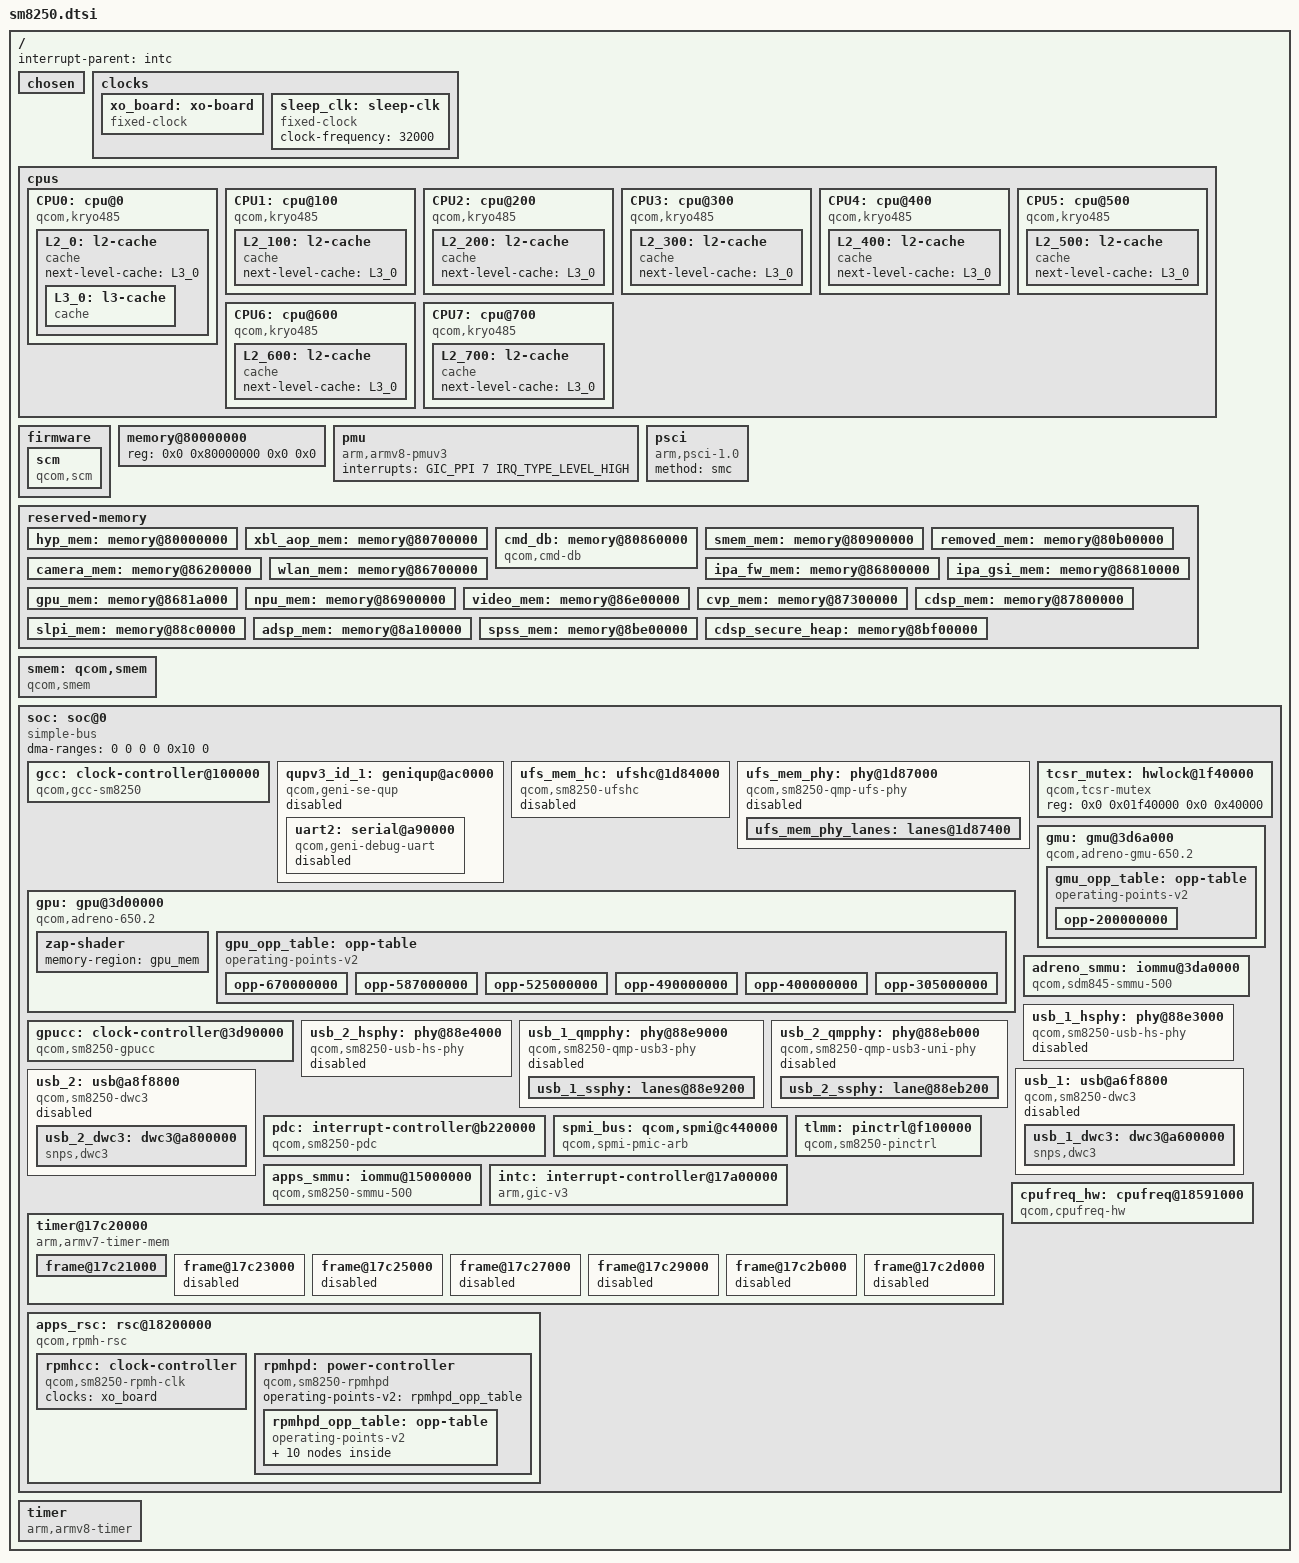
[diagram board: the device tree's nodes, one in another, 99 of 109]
// SPDX-License-Identifier: BSD-3-Clause
/*
 * Copyright (c) 2020, The Linux Foundation. All rights reserved.
 */

#include <dt-bindings/interrupt-controller/arm-gic.h>
#include <dt-bindings/clock/qcom,gcc-sm8250.h>
#include <dt-bindings/clock/qcom,gpucc-sm8250.h>
#include <dt-bindings/clock/qcom,rpmh.h>
#include <dt-bindings/power/qcom-rpmpd.h>
#include <dt-bindings/soc/qcom,rpmh-rsc.h>

/ {
	interrupt-parent = <&intc>;

	#address-cells = <2>;
	#size-cells = <2>;

	chosen { };

	clocks {
		xo_board: xo-board {
			compatible = "fixed-clock";
			#clock-cells = <0>;
			clock-frequency = <38400000>;
			clock-output-names = "xo_board";
		};

		sleep_clk: sleep-clk {
			compatible = "fixed-clock";
			clock-frequency = <32000>;
			#clock-cells = <0>;
		};
	};

	cpus {
		#address-cells = <2>;
		#size-cells = <0>;

		CPU0: cpu@0 {
			device_type = "cpu";
			compatible = "qcom,kryo485";
			reg = <0x0 0x0>;
			enable-method = "psci";
			next-level-cache = <&L2_0>;
			qcom,freq-domain = <&cpufreq_hw 0>;
			L2_0: l2-cache {
			      compatible = "cache";
			      next-level-cache = <&L3_0>;
				L3_0: l3-cache {
				      compatible = "cache";
				};
			};
		};

		CPU1: cpu@100 {
			device_type = "cpu";
			compatible = "qcom,kryo485";
			reg = <0x0 0x100>;
			enable-method = "psci";
			next-level-cache = <&L2_100>;
			qcom,freq-domain = <&cpufreq_hw 0>;
			L2_100: l2-cache {
			      compatible = "cache";
			      next-level-cache = <&L3_0>;
			};
		};

		CPU2: cpu@200 {
			device_type = "cpu";
			compatible = "qcom,kryo485";
			reg = <0x0 0x200>;
			enable-method = "psci";
			next-level-cache = <&L2_200>;
			qcom,freq-domain = <&cpufreq_hw 0>;
			L2_200: l2-cache {
			      compatible = "cache";
			      next-level-cache = <&L3_0>;
			};
		};

		CPU3: cpu@300 {
			device_type = "cpu";
			compatible = "qcom,kryo485";
			reg = <0x0 0x300>;
			enable-method = "psci";
			next-level-cache = <&L2_300>;
			qcom,freq-domain = <&cpufreq_hw 0>;
			L2_300: l2-cache {
			      compatible = "cache";
			      next-level-cache = <&L3_0>;
			};
		};

		CPU4: cpu@400 {
			device_type = "cpu";
			compatible = "qcom,kryo485";
			reg = <0x0 0x400>;
			enable-method = "psci";
			next-level-cache = <&L2_400>;
			qcom,freq-domain = <&cpufreq_hw 1>;
			L2_400: l2-cache {
			      compatible = "cache";
			      next-level-cache = <&L3_0>;
			};
		};

		CPU5: cpu@500 {
			device_type = "cpu";
			compatible = "qcom,kryo485";
			reg = <0x0 0x500>;
			enable-method = "psci";
			next-level-cache = <&L2_500>;
			qcom,freq-domain = <&cpufreq_hw 1>;
			L2_500: l2-cache {
			      compatible = "cache";
			      next-level-cache = <&L3_0>;
			};

		};

		CPU6: cpu@600 {
			device_type = "cpu";
			compatible = "qcom,kryo485";
			reg = <0x0 0x600>;
			enable-method = "psci";
			next-level-cache = <&L2_600>;
			qcom,freq-domain = <&cpufreq_hw 1>;
			L2_600: l2-cache {
			      compatible = "cache";
			      next-level-cache = <&L3_0>;
			};
		};

		CPU7: cpu@700 {
			device_type = "cpu";
			compatible = "qcom,kryo485";
			reg = <0x0 0x700>;
			enable-method = "psci";
			next-level-cache = <&L2_700>;
			qcom,freq-domain = <&cpufreq_hw 2>;
			L2_700: l2-cache {
			      compatible = "cache";
			      next-level-cache = <&L3_0>;
			};
		};
	};

	firmware {
		scm: scm {
			compatible = "qcom,scm";
			#reset-cells = <1>;
		};
	};

	memory@80000000 {
		device_type = "memory";
		/* We expect the bootloader to fill in the size */
		reg = <0x0 0x80000000 0x0 0x0>;
	};

	pmu {
		compatible = "arm,armv8-pmuv3";
		interrupts = <GIC_PPI 7 IRQ_TYPE_LEVEL_HIGH>;
	};

	psci {
		compatible = "arm,psci-1.0";
		method = "smc";
	};

	reserved-memory {
		#address-cells = <2>;
		#size-cells = <2>;
		ranges;

		hyp_mem: memory@80000000 {
			reg = <0x0 0x80000000 0x0 0x600000>;
			no-map;
		};

		xbl_aop_mem: memory@80700000 {
			reg = <0x0 0x80700000 0x0 0x160000>;
			no-map;
		};

		cmd_db: memory@80860000 {
			compatible = "qcom,cmd-db";
			reg = <0x0 0x80860000 0x0 0x20000>;
			no-map;
		};

		smem_mem: memory@80900000 {
			reg = <0x0 0x80900000 0x0 0x200000>;
			no-map;
		};

		removed_mem: memory@80b00000 {
			reg = <0x0 0x80b00000 0x0 0x5300000>;
			no-map;
		};

		camera_mem: memory@86200000 {
			reg = <0x0 0x86200000 0x0 0x500000>;
			no-map;
		};

		wlan_mem: memory@86700000 {
			reg = <0x0 0x86700000 0x0 0x100000>;
			no-map;
		};

		ipa_fw_mem: memory@86800000 {
			reg = <0x0 0x86800000 0x0 0x10000>;
			no-map;
		};

		ipa_gsi_mem: memory@86810000 {
			reg = <0x0 0x86810000 0x0 0xa000>;
			no-map;
		};

		gpu_mem: memory@8681a000 {
			reg = <0x0 0x8681a000 0x0 0x2000>;
			no-map;
		};

		npu_mem: memory@86900000 {
			reg = <0x0 0x86900000 0x0 0x500000>;
			no-map;
		};

		video_mem: memory@86e00000 {
			reg = <0x0 0x86e00000 0x0 0x500000>;
			no-map;
		};

		cvp_mem: memory@87300000 {
			reg = <0x0 0x87300000 0x0 0x500000>;
			no-map;
		};

		cdsp_mem: memory@87800000 {
			reg = <0x0 0x87800000 0x0 0x1400000>;
			no-map;
		};

		slpi_mem: memory@88c00000 {
			reg = <0x0 0x88c00000 0x0 0x1500000>;
			no-map;
		};

		adsp_mem: memory@8a100000 {
			reg = <0x0 0x8a100000 0x0 0x1d00000>;
			no-map;
		};

		spss_mem: memory@8be00000 {
			reg = <0x0 0x8be00000 0x0 0x100000>;
			no-map;
		};

		cdsp_secure_heap: memory@8bf00000 {
			reg = <0x0 0x8bf00000 0x0 0x4600000>;
			no-map;
		};
	};

	smem: qcom,smem {
		compatible = "qcom,smem";
		memory-region = <&smem_mem>;
		hwlocks = <&tcsr_mutex 3>;
	};

	soc: soc@0 {
		#address-cells = <2>;
		#size-cells = <2>;
		ranges = <0 0 0 0 0x10 0>;
		dma-ranges = <0 0 0 0 0x10 0>;
		compatible = "simple-bus";

		gcc: clock-controller@100000 {
			compatible = "qcom,gcc-sm8250";
			reg = <0x0 0x00100000 0x0 0x1f0000>;
			#clock-cells = <1>;
			#reset-cells = <1>;
			#power-domain-cells = <1>;
			clock-names = "bi_tcxo", "sleep_clk";
			clocks = <&rpmhcc RPMH_CXO_CLK>, <&sleep_clk>;
		};

		qupv3_id_1: geniqup@ac0000 {
			compatible = "qcom,geni-se-qup";
			reg = <0x0 0x00ac0000 0x0 0x6000>;
			clock-names = "m-ahb", "s-ahb";
			clocks = <&gcc GCC_QUPV3_WRAP_1_M_AHB_CLK>,
				 <&gcc GCC_QUPV3_WRAP_1_S_AHB_CLK>;
			#address-cells = <2>;
			#size-cells = <2>;
			ranges;
			status = "disabled";

			uart2: serial@a90000 {
				compatible = "qcom,geni-debug-uart";
				reg = <0x0 0x00a90000 0x0 0x4000>;
				clock-names = "se";
				clocks = <&gcc GCC_QUPV3_WRAP1_S4_CLK>;
				interrupts = <GIC_SPI 357 IRQ_TYPE_LEVEL_HIGH>;
				status = "disabled";
			};
		};

		ufs_mem_hc: ufshc@1d84000 {
			compatible = "qcom,sm8250-ufshc", "qcom,ufshc",
				     "jedec,ufs-2.0";
			reg = <0 0x01d84000 0 0x3000>;
			interrupts = <GIC_SPI 265 IRQ_TYPE_LEVEL_HIGH>;
			phys = <&ufs_mem_phy_lanes>;
			phy-names = "ufsphy";
			lanes-per-direction = <2>;
			#reset-cells = <1>;
			resets = <&gcc GCC_UFS_PHY_BCR>;
			reset-names = "rst";

			power-domains = <&gcc UFS_PHY_GDSC>;

			iommus = <&apps_smmu 0x0e0 0>, <&apps_smmu 0x4e0 0>;

			clock-names =
				"core_clk",
				"bus_aggr_clk",
				"iface_clk",
				"core_clk_unipro",
				"ref_clk",
				"tx_lane0_sync_clk",
				"rx_lane0_sync_clk",
				"rx_lane1_sync_clk";
			clocks =
				<&gcc GCC_UFS_PHY_AXI_CLK>,
				<&gcc GCC_AGGRE_UFS_PHY_AXI_CLK>,
				<&gcc GCC_UFS_PHY_AHB_CLK>,
				<&gcc GCC_UFS_PHY_UNIPRO_CORE_CLK>,
				<&rpmhcc RPMH_CXO_CLK>,
				<&gcc GCC_UFS_PHY_TX_SYMBOL_0_CLK>,
				<&gcc GCC_UFS_PHY_RX_SYMBOL_0_CLK>,
				<&gcc GCC_UFS_PHY_RX_SYMBOL_1_CLK>;
			freq-table-hz =
				<37500000 300000000>,
				<0 0>,
				<0 0>,
				<37500000 300000000>,
				<0 0>,
				<0 0>,
				<0 0>,
				<0 0>;

			status = "disabled";
		};

		ufs_mem_phy: phy@1d87000 {
			compatible = "qcom,sm8250-qmp-ufs-phy";
			reg = <0 0x01d87000 0 0x1c0>;
			#address-cells = <2>;
			#size-cells = <2>;
			ranges;
			clock-names = "ref",
				      "ref_aux";
			clocks = <&rpmhcc RPMH_CXO_CLK>,
				 <&gcc GCC_UFS_PHY_PHY_AUX_CLK>;

			resets = <&ufs_mem_hc 0>;
			reset-names = "ufsphy";
			status = "disabled";

			ufs_mem_phy_lanes: lanes@1d87400 {
				reg = <0 0x01d87400 0 0x108>,
				      <0 0x01d87600 0 0x1e0>,
				      <0 0x01d87c00 0 0x1dc>,
				      <0 0x01d87800 0 0x108>,
				      <0 0x01d87a00 0 0x1e0>;
				#phy-cells = <0>;
			};
		};

		tcsr_mutex: hwlock@1f40000 {
			compatible = "qcom,tcsr-mutex";
			reg = <0x0 0x01f40000 0x0 0x40000>;
			#hwlock-cells = <1>;
		};

		gpu: gpu@3d00000 {
			/*
			 * note: the amd,imageon compatible makes it possible
			 * to use the drm/msm driver without the display node,
			 * make sure to remove it when display node is added
			 */
			compatible = "qcom,adreno-650.2",
				     "qcom,adreno",
				     "amd,imageon";
			#stream-id-cells = <16>;

			reg = <0 0x3d00000 0 0x40000>;
			reg-names = "kgsl_3d0_reg_memory";

			interrupts = <GIC_SPI 300 IRQ_TYPE_LEVEL_HIGH>;

			iommus = <&adreno_smmu 0 0x401>;

			operating-points-v2 = <&gpu_opp_table>;

			qcom,gmu = <&gmu>;

			zap-shader {
				memory-region = <&gpu_mem>;
			};

			/* note: downstream checks gpu binning for 670 Mhz */
			gpu_opp_table: opp-table {
				compatible = "operating-points-v2";

				opp-670000000 {
					opp-hz = /bits/ 64 <670000000>;
					opp-level = <RPMH_REGULATOR_LEVEL_NOM_L1>;
				};

				opp-587000000 {
					opp-hz = /bits/ 64 <587000000>;
					opp-level = <RPMH_REGULATOR_LEVEL_NOM>;
				};

				opp-525000000 {
					opp-hz = /bits/ 64 <525000000>;
					opp-level = <RPMH_REGULATOR_LEVEL_SVS_L2>;
				};

				opp-490000000 {
					opp-hz = /bits/ 64 <490000000>;
					opp-level = <RPMH_REGULATOR_LEVEL_SVS_L1>;
				};

				/* opp-441600000 {
					opp-hz = /bits/ 64 <441600000>;
					opp-level = <RPMH_REGULATOR_LEVEL_SVS_L0>;
				}; */

				opp-400000000 {
					opp-hz = /bits/ 64 <400000000>;
					opp-level = <RPMH_REGULATOR_LEVEL_SVS>;
				};

				opp-305000000 {
					opp-hz = /bits/ 64 <305000000>;
					opp-level = <RPMH_REGULATOR_LEVEL_LOW_SVS>;
				};
			};
		};

		gmu: gmu@3d6a000 {
			compatible="qcom,adreno-gmu-650.2", "qcom,adreno-gmu";

			reg = <0 0x3d6a000 0 0x30000>,
			      <0 0x3de0000 0 0x10000>,
			      <0 0xb290000 0 0x10000>,
			      <0 0xb490000 0 0x10000>;
			reg-names = "gmu", "rscc", "gmu_pdc", "gmu_pdc_seq";

			interrupts = <GIC_SPI 304 IRQ_TYPE_LEVEL_HIGH>,
				     <GIC_SPI 305 IRQ_TYPE_LEVEL_HIGH>;
			interrupt-names = "hfi", "gmu";

			clocks = <&gpucc GPU_CC_AHB_CLK>,
				 <&gpucc GPU_CC_CX_GMU_CLK>,
			         <&gpucc GPU_CC_CXO_CLK>,
				 <&gcc GCC_DDRSS_GPU_AXI_CLK>,
				 <&gcc GCC_GPU_MEMNOC_GFX_CLK>;
			clock-names = "ahb", "gmu", "cxo", "axi", "memnoc";

			power-domains = <&gpucc GPU_CX_GDSC>,
					<&gpucc GPU_GX_GDSC>;
			power-domain-names = "cx", "gx";

			iommus = <&adreno_smmu 5 0x400>;

			operating-points-v2 = <&gmu_opp_table>;

			gmu_opp_table: opp-table {
				compatible = "operating-points-v2";

				opp-200000000 {
					opp-hz = /bits/ 64 <200000000>;
					opp-level = <RPMH_REGULATOR_LEVEL_MIN_SVS>;
				};
			};
		};

		gpucc: clock-controller@3d90000 {
			compatible = "qcom,sm8250-gpucc";
			reg = <0 0x3d90000 0 0x9000>;
			#clock-cells = <1>;
			#reset-cells = <1>;
			#power-domain-cells = <1>;
			clocks = <&rpmhcc RPMH_CXO_CLK>;
			clock-names = "xo";
		};

		adreno_smmu: iommu@3da0000 {
			compatible = "qcom,sdm845-smmu-500", "arm,mmu-500";
			reg = <0 0x3da0000 0 0x10000>;
			#iommu-cells = <2>;
			#global-interrupts = <2>;
			interrupts = <GIC_SPI 672 IRQ_TYPE_LEVEL_HIGH>,
				     <GIC_SPI 673 IRQ_TYPE_LEVEL_HIGH>,
				     <GIC_SPI 678 IRQ_TYPE_LEVEL_HIGH>,
				     <GIC_SPI 679 IRQ_TYPE_LEVEL_HIGH>,
				     <GIC_SPI 680 IRQ_TYPE_LEVEL_HIGH>,
				     <GIC_SPI 681 IRQ_TYPE_LEVEL_HIGH>,
				     <GIC_SPI 682 IRQ_TYPE_LEVEL_HIGH>,
				     <GIC_SPI 683 IRQ_TYPE_LEVEL_HIGH>,
				     <GIC_SPI 684 IRQ_TYPE_LEVEL_HIGH>,
				     <GIC_SPI 685 IRQ_TYPE_LEVEL_HIGH>;
			clocks = <&gpucc GPU_CC_AHB_CLK>,
				 <&gcc GCC_GPU_MEMNOC_GFX_CLK>,
				 <&gcc GCC_GPU_SNOC_DVM_GFX_CLK>;
			clock-names = "ahb", "bus", "iface";

			power-domains = <&gpucc GPU_CX_GDSC>;
		};

		usb_1_hsphy: phy@88e3000 {
			compatible = "qcom,sm8250-usb-hs-phy",
				     "qcom,usb-snps-hs-7nm-phy";
			reg = <0 0x088e3000 0 0x400>;
			status = "disabled";
			#phy-cells = <0>;

			clocks = <&rpmhcc RPMH_CXO_CLK>;
			clock-names = "ref";

			resets = <&gcc GCC_QUSB2PHY_PRIM_BCR>;
		};

		usb_2_hsphy: phy@88e4000 {
			compatible = "qcom,sm8250-usb-hs-phy",
				     "qcom,usb-snps-hs-7nm-phy";
			reg = <0 0x088e4000 0 0x400>;
			status = "disabled";
			#phy-cells = <0>;

			clocks = <&rpmhcc RPMH_CXO_CLK>;
			clock-names = "ref";

			resets = <&gcc GCC_QUSB2PHY_SEC_BCR>;
		};

		usb_1_qmpphy: phy@88e9000 {
			compatible = "qcom,sm8250-qmp-usb3-phy";
			reg = <0 0x088e9000 0 0x200>,
			      <0 0x088e8000 0 0x20>;
			reg-names = "reg-base", "dp_com";
			status = "disabled";
			#clock-cells = <1>;
			#address-cells = <2>;
			#size-cells = <2>;
			ranges;

			clocks = <&gcc GCC_USB3_PRIM_PHY_AUX_CLK>,
				 <&rpmhcc RPMH_CXO_CLK>,
				 <&gcc GCC_USB3_PRIM_PHY_COM_AUX_CLK>;
			clock-names = "aux", "ref_clk_src", "com_aux";

			resets = <&gcc GCC_USB3_DP_PHY_PRIM_BCR>,
				 <&gcc GCC_USB3_PHY_PRIM_BCR>;
			reset-names = "phy", "common";

			usb_1_ssphy: lanes@88e9200 {
				reg = <0 0x088e9200 0 0x200>,
				      <0 0x088e9400 0 0x200>,
				      <0 0x088e9c00 0 0x400>,
				      <0 0x088e9600 0 0x200>,
				      <0 0x088e9800 0 0x200>,
				      <0 0x088e9a00 0 0x100>;
				#phy-cells = <0>;
				clocks = <&gcc GCC_USB3_PRIM_PHY_PIPE_CLK>;
				clock-names = "pipe0";
				clock-output-names = "usb3_phy_pipe_clk_src";
			};
		};

		usb_2_qmpphy: phy@88eb000 {
			compatible = "qcom,sm8250-qmp-usb3-uni-phy";
			reg = <0 0x088eb000 0 0x200>;
			status = "disabled";
			#clock-cells = <1>;
			#address-cells = <2>;
			#size-cells = <2>;
			ranges;

			clocks = <&gcc GCC_USB3_SEC_PHY_AUX_CLK>,
				 <&rpmhcc RPMH_CXO_CLK>,
				 <&gcc GCC_USB3_SEC_CLKREF_EN>,
				 <&gcc GCC_USB3_SEC_PHY_COM_AUX_CLK>;
			clock-names = "aux", "ref_clk_src", "ref", "com_aux";

			resets = <&gcc GCC_USB3PHY_PHY_SEC_BCR>,
				 <&gcc GCC_USB3_PHY_SEC_BCR>;
			reset-names = "phy", "common";

			usb_2_ssphy: lane@88eb200 {
				reg = <0 0x088eb200 0 0x200>,
				      <0 0x088eb400 0 0x200>,
				      <0 0x088eb800 0 0x800>;
				#phy-cells = <0>;
				clocks = <&gcc GCC_USB3_SEC_PHY_PIPE_CLK>;
				clock-names = "pipe0";
				clock-output-names = "usb3_uni_phy_pipe_clk_src";
			};
		};

		usb_1: usb@a6f8800 {
			compatible = "qcom,sm8250-dwc3", "qcom,dwc3";
			reg = <0 0x0a6f8800 0 0x400>;
			status = "disabled";
			#address-cells = <2>;
			#size-cells = <2>;
			ranges;
			dma-ranges;

			clocks = <&gcc GCC_CFG_NOC_USB3_PRIM_AXI_CLK>,
				 <&gcc GCC_USB30_PRIM_MASTER_CLK>,
				 <&gcc GCC_AGGRE_USB3_PRIM_AXI_CLK>,
				 <&gcc GCC_USB30_PRIM_MOCK_UTMI_CLK>,
				 <&gcc GCC_USB30_PRIM_SLEEP_CLK>,
				 <&gcc GCC_USB3_SEC_CLKREF_EN>;
			clock-names = "cfg_noc", "core", "iface", "mock_utmi",
				      "sleep", "xo";

			assigned-clocks = <&gcc GCC_USB30_PRIM_MOCK_UTMI_CLK>,
					  <&gcc GCC_USB30_PRIM_MASTER_CLK>;
			assigned-clock-rates = <19200000>, <200000000>;

			interrupts-extended = <&intc GIC_SPI 131 IRQ_TYPE_LEVEL_HIGH>,
					      <&pdc 14 IRQ_TYPE_EDGE_BOTH>,
					      <&pdc 15 IRQ_TYPE_EDGE_BOTH>,
					      <&pdc 17 IRQ_TYPE_LEVEL_HIGH>;
			interrupt-names = "hs_phy_irq", "dp_hs_phy_irq",
					  "dm_hs_phy_irq", "ss_phy_irq";

			power-domains = <&gcc USB30_PRIM_GDSC>;

			resets = <&gcc GCC_USB30_PRIM_BCR>;

			usb_1_dwc3: dwc3@a600000 {
				compatible = "snps,dwc3";
				reg = <0 0x0a600000 0 0xcd00>;
				interrupts = <GIC_SPI 133 IRQ_TYPE_LEVEL_HIGH>;
				iommus = <&apps_smmu 0x0 0x0>;
				snps,dis_u2_susphy_quirk;
				snps,dis_enblslpm_quirk;
				phys = <&usb_1_hsphy>, <&usb_1_ssphy>;
				phy-names = "usb2-phy", "usb3-phy";
			};
		};

		usb_2: usb@a8f8800 {
			compatible = "qcom,sm8250-dwc3", "qcom,dwc3";
			reg = <0 0x0a8f8800 0 0x400>;
			status = "disabled";
			#address-cells = <2>;
			#size-cells = <2>;
			ranges;
			dma-ranges;

			clocks = <&gcc GCC_CFG_NOC_USB3_SEC_AXI_CLK>,
				 <&gcc GCC_USB30_SEC_MASTER_CLK>,
				 <&gcc GCC_AGGRE_USB3_SEC_AXI_CLK>,
				 <&gcc GCC_USB30_SEC_MOCK_UTMI_CLK>,
				 <&gcc GCC_USB30_SEC_SLEEP_CLK>,
				 <&gcc GCC_USB3_SEC_CLKREF_EN>;
			clock-names = "cfg_noc", "core", "iface", "mock_utmi",
				      "sleep", "xo";

			assigned-clocks = <&gcc GCC_USB30_SEC_MOCK_UTMI_CLK>,
					  <&gcc GCC_USB30_SEC_MASTER_CLK>;
			assigned-clock-rates = <19200000>, <200000000>;

			interrupts-extended = <&intc GIC_SPI 136 IRQ_TYPE_LEVEL_HIGH>,
					      <&pdc 12 IRQ_TYPE_EDGE_BOTH>,
					      <&pdc 13 IRQ_TYPE_EDGE_BOTH>,
					      <&pdc 16 IRQ_TYPE_LEVEL_HIGH>;
			interrupt-names = "hs_phy_irq", "dp_hs_phy_irq",
					  "dm_hs_phy_irq", "ss_phy_irq";

			power-domains = <&gcc USB30_SEC_GDSC>;

			resets = <&gcc GCC_USB30_SEC_BCR>;

			usb_2_dwc3: dwc3@a800000 {
				compatible = "snps,dwc3";
				reg = <0 0x0a800000 0 0xcd00>;
				interrupts = <GIC_SPI 138 IRQ_TYPE_LEVEL_HIGH>;
				iommus = <&apps_smmu 0x20 0>;
				snps,dis_u2_susphy_quirk;
				snps,dis_enblslpm_quirk;
				phys = <&usb_2_hsphy>, <&usb_2_ssphy>;
				phy-names = "usb2-phy", "usb3-phy";
			};
		};

		pdc: interrupt-controller@b220000 {
			compatible = "qcom,sm8250-pdc", "qcom,pdc";
			reg = <0 0x0b220000 0 0x30000>, <0 0x17c000f0 0 0x60>;
			qcom,pdc-ranges = <0 480 94>, <94 609 31>,
					  <125 63 1>, <126 716 12>;
			#interrupt-cells = <2>;
			interrupt-parent = <&intc>;
			interrupt-controller;
		};

		spmi_bus: qcom,spmi@c440000 {
			compatible = "qcom,spmi-pmic-arb";
			reg = <0x0 0x0c440000 0x0 0x0001100>,
			      <0x0 0x0c600000 0x0 0x2000000>,
			      <0x0 0x0e600000 0x0 0x0100000>,
			      <0x0 0x0e700000 0x0 0x00a0000>,
			      <0x0 0x0c40a000 0x0 0x0026000>;
			reg-names = "core", "chnls", "obsrvr", "intr", "cnfg";
			interrupt-names = "periph_irq";
			interrupts-extended = <&pdc 1 IRQ_TYPE_LEVEL_HIGH>;
			qcom,ee = <0>;
			qcom,channel = <0>;
			#address-cells = <2>;
			#size-cells = <0>;
			interrupt-controller;
			#interrupt-cells = <4>;
		};

		tlmm: pinctrl@f100000 {
			compatible = "qcom,sm8250-pinctrl";
			reg = <0 0x0f100000 0 0x300000>,
			      <0 0x0f500000 0 0x300000>,
			      <0 0x0f900000 0 0x300000>;
			reg-names = "west", "south", "north";
			interrupts = <GIC_SPI 208 IRQ_TYPE_LEVEL_HIGH>;
			gpio-controller;
			#gpio-cells = <2>;
			interrupt-controller;
			#interrupt-cells = <2>;
			gpio-ranges = <&tlmm 0 0 180>;
			wakeup-parent = <&pdc>;
		};

		apps_smmu: iommu@15000000 {
			compatible = "qcom,sm8250-smmu-500", "arm,mmu-500";
			reg = <0 0x15000000 0 0x100000>;
			#iommu-cells = <2>;
			#global-interrupts = <2>;
			interrupts =    <GIC_SPI 64 IRQ_TYPE_LEVEL_HIGH>,
					<GIC_SPI 65 IRQ_TYPE_LEVEL_HIGH>,
					<GIC_SPI 97 IRQ_TYPE_LEVEL_HIGH>,
					<GIC_SPI 98 IRQ_TYPE_LEVEL_HIGH>,
					<GIC_SPI 99 IRQ_TYPE_LEVEL_HIGH>,
					<GIC_SPI 100 IRQ_TYPE_LEVEL_HIGH>,
					<GIC_SPI 101 IRQ_TYPE_LEVEL_HIGH>,
					<GIC_SPI 102 IRQ_TYPE_LEVEL_HIGH>,
					<GIC_SPI 103 IRQ_TYPE_LEVEL_HIGH>,
					<GIC_SPI 104 IRQ_TYPE_LEVEL_HIGH>,
					<GIC_SPI 105 IRQ_TYPE_LEVEL_HIGH>,
					<GIC_SPI 106 IRQ_TYPE_LEVEL_HIGH>,
					<GIC_SPI 107 IRQ_TYPE_LEVEL_HIGH>,
					<GIC_SPI 108 IRQ_TYPE_LEVEL_HIGH>,
					<GIC_SPI 109 IRQ_TYPE_LEVEL_HIGH>,
					<GIC_SPI 110 IRQ_TYPE_LEVEL_HIGH>,
					<GIC_SPI 111 IRQ_TYPE_LEVEL_HIGH>,
					<GIC_SPI 112 IRQ_TYPE_LEVEL_HIGH>,
					<GIC_SPI 113 IRQ_TYPE_LEVEL_HIGH>,
					<GIC_SPI 114 IRQ_TYPE_LEVEL_HIGH>,
					<GIC_SPI 115 IRQ_TYPE_LEVEL_HIGH>,
					<GIC_SPI 116 IRQ_TYPE_LEVEL_HIGH>,
					<GIC_SPI 117 IRQ_TYPE_LEVEL_HIGH>,
					<GIC_SPI 118 IRQ_TYPE_LEVEL_HIGH>,
					<GIC_SPI 181 IRQ_TYPE_LEVEL_HIGH>,
					<GIC_SPI 182 IRQ_TYPE_LEVEL_HIGH>,
					<GIC_SPI 183 IRQ_TYPE_LEVEL_HIGH>,
					<GIC_SPI 184 IRQ_TYPE_LEVEL_HIGH>,
					<GIC_SPI 185 IRQ_TYPE_LEVEL_HIGH>,
					<GIC_SPI 186 IRQ_TYPE_LEVEL_HIGH>,
					<GIC_SPI 187 IRQ_TYPE_LEVEL_HIGH>,
					<GIC_SPI 188 IRQ_TYPE_LEVEL_HIGH>,
					<GIC_SPI 189 IRQ_TYPE_LEVEL_HIGH>,
					<GIC_SPI 190 IRQ_TYPE_LEVEL_HIGH>,
					<GIC_SPI 191 IRQ_TYPE_LEVEL_HIGH>,
					<GIC_SPI 192 IRQ_TYPE_LEVEL_HIGH>,
					<GIC_SPI 315 IRQ_TYPE_LEVEL_HIGH>,
					<GIC_SPI 316 IRQ_TYPE_LEVEL_HIGH>,
					<GIC_SPI 317 IRQ_TYPE_LEVEL_HIGH>,
					<GIC_SPI 318 IRQ_TYPE_LEVEL_HIGH>,
					<GIC_SPI 319 IRQ_TYPE_LEVEL_HIGH>,
					<GIC_SPI 320 IRQ_TYPE_LEVEL_HIGH>,
					<GIC_SPI 321 IRQ_TYPE_LEVEL_HIGH>,
					<GIC_SPI 322 IRQ_TYPE_LEVEL_HIGH>,
					<GIC_SPI 323 IRQ_TYPE_LEVEL_HIGH>,
					<GIC_SPI 324 IRQ_TYPE_LEVEL_HIGH>,
					<GIC_SPI 325 IRQ_TYPE_LEVEL_HIGH>,
					<GIC_SPI 326 IRQ_TYPE_LEVEL_HIGH>,
					<GIC_SPI 327 IRQ_TYPE_LEVEL_HIGH>,
					<GIC_SPI 328 IRQ_TYPE_LEVEL_HIGH>,
					<GIC_SPI 329 IRQ_TYPE_LEVEL_HIGH>,
					<GIC_SPI 330 IRQ_TYPE_LEVEL_HIGH>,
					<GIC_SPI 331 IRQ_TYPE_LEVEL_HIGH>,
					<GIC_SPI 332 IRQ_TYPE_LEVEL_HIGH>,
					<GIC_SPI 333 IRQ_TYPE_LEVEL_HIGH>,
					<GIC_SPI 334 IRQ_TYPE_LEVEL_HIGH>,
					<GIC_SPI 335 IRQ_TYPE_LEVEL_HIGH>,
					<GIC_SPI 336 IRQ_TYPE_LEVEL_HIGH>,
					<GIC_SPI 337 IRQ_TYPE_LEVEL_HIGH>,
					<GIC_SPI 338 IRQ_TYPE_LEVEL_HIGH>,
					<GIC_SPI 339 IRQ_TYPE_LEVEL_HIGH>,
					<GIC_SPI 340 IRQ_TYPE_LEVEL_HIGH>,
					<GIC_SPI 341 IRQ_TYPE_LEVEL_HIGH>,
					<GIC_SPI 342 IRQ_TYPE_LEVEL_HIGH>,
					<GIC_SPI 343 IRQ_TYPE_LEVEL_HIGH>,
					<GIC_SPI 344 IRQ_TYPE_LEVEL_HIGH>,
					<GIC_SPI 345 IRQ_TYPE_LEVEL_HIGH>,
					<GIC_SPI 395 IRQ_TYPE_LEVEL_HIGH>,
					<GIC_SPI 396 IRQ_TYPE_LEVEL_HIGH>,
					<GIC_SPI 397 IRQ_TYPE_LEVEL_HIGH>,
					<GIC_SPI 398 IRQ_TYPE_LEVEL_HIGH>,
					<GIC_SPI 399 IRQ_TYPE_LEVEL_HIGH>,
					<GIC_SPI 400 IRQ_TYPE_LEVEL_HIGH>,
					<GIC_SPI 401 IRQ_TYPE_LEVEL_HIGH>,
					<GIC_SPI 402 IRQ_TYPE_LEVEL_HIGH>,
					<GIC_SPI 403 IRQ_TYPE_LEVEL_HIGH>,
					<GIC_SPI 404 IRQ_TYPE_LEVEL_HIGH>,
					<GIC_SPI 405 IRQ_TYPE_LEVEL_HIGH>,
					<GIC_SPI 406 IRQ_TYPE_LEVEL_HIGH>,
					<GIC_SPI 407 IRQ_TYPE_LEVEL_HIGH>,
					<GIC_SPI 408 IRQ_TYPE_LEVEL_HIGH>,
					<GIC_SPI 409 IRQ_TYPE_LEVEL_HIGH>,
					<GIC_SPI 412 IRQ_TYPE_LEVEL_HIGH>,
					<GIC_SPI 418 IRQ_TYPE_LEVEL_HIGH>,
					<GIC_SPI 419 IRQ_TYPE_LEVEL_HIGH>,
					<GIC_SPI 421 IRQ_TYPE_LEVEL_HIGH>,
					<GIC_SPI 423 IRQ_TYPE_LEVEL_HIGH>,
					<GIC_SPI 424 IRQ_TYPE_LEVEL_HIGH>,
					<GIC_SPI 425 IRQ_TYPE_LEVEL_HIGH>,
					<GIC_SPI 690 IRQ_TYPE_LEVEL_HIGH>,
					<GIC_SPI 691 IRQ_TYPE_LEVEL_HIGH>,
					<GIC_SPI 692 IRQ_TYPE_LEVEL_HIGH>,
					<GIC_SPI 693 IRQ_TYPE_LEVEL_HIGH>,
					<GIC_SPI 694 IRQ_TYPE_LEVEL_HIGH>,
					<GIC_SPI 695 IRQ_TYPE_LEVEL_HIGH>,
					<GIC_SPI 696 IRQ_TYPE_LEVEL_HIGH>,
					<GIC_SPI 697 IRQ_TYPE_LEVEL_HIGH>,
					<GIC_SPI 707 IRQ_TYPE_LEVEL_HIGH>;
		};

		intc: interrupt-controller@17a00000 {
			compatible = "arm,gic-v3";
			#interrupt-cells = <3>;
			interrupt-controller;
			reg = <0x0 0x17a00000 0x0 0x10000>,     /* GICD */
			      <0x0 0x17a60000 0x0 0x100000>;    /* GICR * 8 */
			interrupts = <GIC_PPI 9 IRQ_TYPE_LEVEL_HIGH>;
		};

		timer@17c20000 {
			#address-cells = <2>;
			#size-cells = <2>;
			ranges;
			compatible = "arm,armv7-timer-mem";
			reg = <0x0 0x17c20000 0x0 0x1000>;
			clock-frequency = <19200000>;

			frame@17c21000 {
				frame-number = <0>;
				interrupts = <GIC_SPI 8 IRQ_TYPE_LEVEL_HIGH>,
					     <GIC_SPI 6 IRQ_TYPE_LEVEL_HIGH>;
				reg = <0x0 0x17c21000 0x0 0x1000>,
				      <0x0 0x17c22000 0x0 0x1000>;
			};

			frame@17c23000 {
				frame-number = <1>;
				interrupts = <GIC_SPI 9 IRQ_TYPE_LEVEL_HIGH>;
				reg = <0x0 0x17c23000 0x0 0x1000>;
				status = "disabled";
			};

			frame@17c25000 {
				frame-number = <2>;
				interrupts = <GIC_SPI 10 IRQ_TYPE_LEVEL_HIGH>;
				reg = <0x0 0x17c25000 0x0 0x1000>;
				status = "disabled";
			};

			frame@17c27000 {
				frame-number = <3>;
				interrupts = <GIC_SPI 11 IRQ_TYPE_LEVEL_HIGH>;
				reg = <0x0 0x17c27000 0x0 0x1000>;
				status = "disabled";
			};

			frame@17c29000 {
				frame-number = <4>;
				interrupts = <GIC_SPI 12 IRQ_TYPE_LEVEL_HIGH>;
				reg = <0x0 0x17c29000 0x0 0x1000>;
				status = "disabled";
			};

			frame@17c2b000 {
				frame-number = <5>;
				interrupts = <GIC_SPI 13 IRQ_TYPE_LEVEL_HIGH>;
				reg = <0x0 0x17c2b000 0x0 0x1000>;
				status = "disabled";
			};

			frame@17c2d000 {
				frame-number = <6>;
				interrupts = <GIC_SPI 14 IRQ_TYPE_LEVEL_HIGH>;
				reg = <0x0 0x17c2d000 0x0 0x1000>;
				status = "disabled";
			};
		};

		apps_rsc: rsc@18200000 {
			label = "apps_rsc";
			compatible = "qcom,rpmh-rsc";
			reg = <0x0 0x18200000 0x0 0x10000>,
				<0x0 0x18210000 0x0 0x10000>,
				<0x0 0x18220000 0x0 0x10000>;
			reg-names = "drv-0", "drv-1", "drv-2";
			interrupts = <GIC_SPI 3 IRQ_TYPE_LEVEL_HIGH>,
				     <GIC_SPI 4 IRQ_TYPE_LEVEL_HIGH>,
				     <GIC_SPI 5 IRQ_TYPE_LEVEL_HIGH>;
			qcom,tcs-offset = <0xd00>;
			qcom,drv-id = <2>;
			qcom,tcs-config = <ACTIVE_TCS  2>, <SLEEP_TCS   3>,
					  <WAKE_TCS    3>, <CONTROL_TCS 1>;

			rpmhcc: clock-controller {
				compatible = "qcom,sm8250-rpmh-clk";
				#clock-cells = <1>;
				clock-names = "xo";
				clocks = <&xo_board>;
			};

			rpmhpd: power-controller {
				compatible = "qcom,sm8250-rpmhpd";
				#power-domain-cells = <1>;
				operating-points-v2 = <&rpmhpd_opp_table>;

				rpmhpd_opp_table: opp-table {
					compatible = "operating-points-v2";

					rpmhpd_opp_ret: opp1 {
						opp-level = <RPMH_REGULATOR_LEVEL_RETENTION>;
					};

					rpmhpd_opp_min_svs: opp2 {
						opp-level = <RPMH_REGULATOR_LEVEL_MIN_SVS>;
					};

					rpmhpd_opp_low_svs: opp3 {
						opp-level = <RPMH_REGULATOR_LEVEL_LOW_SVS>;
					};

					rpmhpd_opp_svs: opp4 {
						opp-level = <RPMH_REGULATOR_LEVEL_SVS>;
					};

					rpmhpd_opp_svs_l1: opp5 {
						opp-level = <RPMH_REGULATOR_LEVEL_SVS_L1>;
					};

					rpmhpd_opp_nom: opp6 {
						opp-level = <RPMH_REGULATOR_LEVEL_NOM>;
					};

					rpmhpd_opp_nom_l1: opp7 {
						opp-level = <RPMH_REGULATOR_LEVEL_NOM_L1>;
					};

					rpmhpd_opp_nom_l2: opp8 {
						opp-level = <RPMH_REGULATOR_LEVEL_NOM_L2>;
					};

					rpmhpd_opp_turbo: opp9 {
						opp-level = <RPMH_REGULATOR_LEVEL_TURBO>;
					};

					rpmhpd_opp_turbo_l1: opp10 {
						opp-level = <RPMH_REGULATOR_LEVEL_TURBO_L1>;
					};
				};
			};
		};

		cpufreq_hw: cpufreq@18591000 {
			compatible = "qcom,cpufreq-hw";
			reg = <0 0x18591000 0 0x1000>,
			      <0 0x18592000 0 0x1000>,
			      <0 0x18593000 0 0x1000>;
			reg-names = "freq-domain0", "freq-domain1",
				    "freq-domain2";

			clocks = <&rpmhcc RPMH_CXO_CLK>, <&gcc GPLL0>;
			clock-names = "xo", "alternate";

			#freq-domain-cells = <1>;
		};
	};

	timer {
		compatible = "arm,armv8-timer";
		interrupts = <GIC_PPI 13
				(GIC_CPU_MASK_SIMPLE(8) | IRQ_TYPE_LEVEL_LOW)>,
			     <GIC_PPI 14
				(GIC_CPU_MASK_SIMPLE(8) | IRQ_TYPE_LEVEL_LOW)>,
			     <GIC_PPI 11
				(GIC_CPU_MASK_SIMPLE(8) | IRQ_TYPE_LEVEL_LOW)>,
			     <GIC_PPI 12
				(GIC_CPU_MASK_SIMPLE(8) | IRQ_TYPE_LEVEL_LOW)>;
	};
};
